# CORTEXM0: IP-XACT component
VLNV arm.com:Cortex-M0:CORTEXM0:r0p0_0

## Parameters
 = 
 = 
 = 
 = 
 = 
 = 
 = 
 = 
 = 
 = 
 = 
 = 

## Bus interfaces (logical=physical port)
AHBLite: master amba.com:AMBA3:AHBLite:r1p0_6, address space AHBLite
CortexM0_SMP: master arm.com:Cortex-M0:cm0_smp:r0p0_0
WICInterface: master arm.com:Cortex-M0:cm0_proc_wicinterface:r0p0_0
SCLK: slave arm.com:Cortex-M0:cm0_system_clk:r0p0_0
DebugTriggers: slave arm.com:CortexMCores:dbg_trigger_bus:r0p0_1
DebugSlave: slave arm.com:Cortex-M0:cm0_debug_slave:r0p0_0, memory map debug_memory
Events: master arm.com:CortexMCores:sleep_bus:r0p0_1
IRQ0: slave spiritconsortium.org:busdef.interrupt:interrupt:1.0
IRQ1: slave spiritconsortium.org:busdef.interrupt:interrupt:1.0
IRQ2: slave spiritconsortium.org:busdef.interrupt:interrupt:1.0
IRQ3: slave spiritconsortium.org:busdef.interrupt:interrupt:1.0
IRQ4: slave spiritconsortium.org:busdef.interrupt:interrupt:1.0
IRQ5: slave spiritconsortium.org:busdef.interrupt:interrupt:1.0
IRQ6: slave spiritconsortium.org:busdef.interrupt:interrupt:1.0
IRQ7: slave spiritconsortium.org:busdef.interrupt:interrupt:1.0
IRQ8: slave spiritconsortium.org:busdef.interrupt:interrupt:1.0
IRQ9: slave spiritconsortium.org:busdef.interrupt:interrupt:1.0
IRQ10: slave spiritconsortium.org:busdef.interrupt:interrupt:1.0
IRQ11: slave spiritconsortium.org:busdef.interrupt:interrupt:1.0
IRQ12: slave spiritconsortium.org:busdef.interrupt:interrupt:1.0
IRQ13: slave spiritconsortium.org:busdef.interrupt:interrupt:1.0
IRQ14: slave spiritconsortium.org:busdef.interrupt:interrupt:1.0
IRQ15: slave spiritconsortium.org:busdef.interrupt:interrupt:1.0
IRQ16: slave spiritconsortium.org:busdef.interrupt:interrupt:1.0
IRQ17: slave spiritconsortium.org:busdef.interrupt:interrupt:1.0
IRQ18: slave spiritconsortium.org:busdef.interrupt:interrupt:1.0
IRQ19: slave spiritconsortium.org:busdef.interrupt:interrupt:1.0
IRQ20: slave spiritconsortium.org:busdef.interrupt:interrupt:1.0
IRQ21: slave spiritconsortium.org:busdef.interrupt:interrupt:1.0
IRQ22: slave spiritconsortium.org:busdef.interrupt:interrupt:1.0
IRQ23: slave spiritconsortium.org:busdef.interrupt:interrupt:1.0
IRQ24: slave spiritconsortium.org:busdef.interrupt:interrupt:1.0
IRQ25: slave spiritconsortium.org:busdef.interrupt:interrupt:1.0
IRQ26: slave spiritconsortium.org:busdef.interrupt:interrupt:1.0
IRQ27: slave spiritconsortium.org:busdef.interrupt:interrupt:1.0
IRQ28: slave spiritconsortium.org:busdef.interrupt:interrupt:1.0
IRQ29: slave spiritconsortium.org:busdef.interrupt:interrupt:1.0
IRQ30: slave spiritconsortium.org:busdef.interrupt:interrupt:1.0
IRQ31: slave spiritconsortium.org:busdef.interrupt:interrupt:1.0
NMI: slave spiritconsortium.org:busdef.interrupt:interrupt:1.0

## Address spaces and blocks
AHBLite: range 3584M, width 32
Vendor_SYS: range 511M, width 32
PPB: range 1M, width 32
debug_memory.: base 0xE0001000, range 4K, width 32
debug_memory.: base 0xE0002000, range 4K, width 32
debug_memory.: base 0xE000E000, range 3K, width 32
debug_memory.: base 0xE000ED00, range 768, width 32
debug_memory.: base 0xE00FF000, range 4K, width 32
debug_memory.: base 0xE000E000, range 4K, width 32
debug_memory.: base 0xE0001000, range 4K, width 32
debug_memory.: base 0xE0002000, range 4K, width 32

## Registers
Registers are 32-bit, read-only, reset 0x0 unless marked. A register's access mark holds for its fields unless they carry their own. Offsets are from the block's base; lines under a group give offsets from that group; [hi:lo] are bit positions; {n}, {i} and the like mark numbered series; 'fields as' and 'values as' point back to an identical list; <NAME> marks a mode.

## debug_memory.block0
Base 0xE0001000
0x00 DWT_CTRL reset 0x20000000 (reset mask 0xEFFFFFFF) — Use the DW Control Register to check how many comparators are available.
  [31:28] NUMCOMP — Number of comparators. This read-only field contains 0b0010 or 0b0001 to indicate two or one comparators.
    2=Indicates two comparators; 1=Indicates one comparator
0x1C DWT_PCSR reset not defined — Use the DW Program Counter Sample Register (DWPCSR) to enable coarse-grained software profiling using a debug agent, without changing the currently executing code. If the core is not in debug state, the value returned is the instruction address of a recently executed instruction. If the core is in debug state, the value returned is 0xFFFFFFFF.
  [31:0] EIASAMPLE — Execution instruction address sample, or 0xFFFFFFFF if the core is halted
0x20 DWT_COMP0 rw reset not defined — Use the DW Comparator Registers to write the values that trigger watchpoint events
  [31:0] COMP — Value to compare against PC or the data address as given by the DWT_FUNCTION Register. A debugger must align the value to DWT_MASK, otherwise operation is UNPREDICTABLE.
0x24 DWT_MASK0 rw reset not defined — Use the DW Mask Registers to apply a mask to data addresses when matching against COMP
  [3:0] MASK — Mask applied to data address when matching against COMP. This is the size of the ignore mask.
0x28 DWT_FUNCTION0 rw reset not defined — Use the DW Function Registers to control the operation of the comparator. Each comparator can Match against either the PC or the data address and halt the core. This function is in conjunction with DWT_COMP
  [3:0] FUNCTION — Function setting
    0=Disabled; 4=Watchpoint on PC match; 5=Watchpoint on read address; 6=Watchpoint on write to address; 7=Watchpoint on read or write address
0x30 DWT_COMP1 rw reset not defined — Use the DW Comparator Registers to write the values that trigger watchpoint events
  [31:0] COMP — Value to compare against PC or the data address as given by the DWT_FUNCTION Register. A debugger must align this value to DWT_MASK, otherwise operation is UNPREDICTABLE.
0x34 DWT_MASK1 rw reset not defined — Use the DW Mask Registers to apply a mask to data addresses when matching against COMP
  fields as DWT_MASK0
0x38 DWT_FUNCTION1 rw — Use the DW Function Registers to control the operation of the comparator. Each comparator can Match against either the PC or the data address and halt the core. This function is in conjunction with DWT_COMP
  fields as DWT_FUNCTION0

## debug_memory.block1
Base 0xE0002000
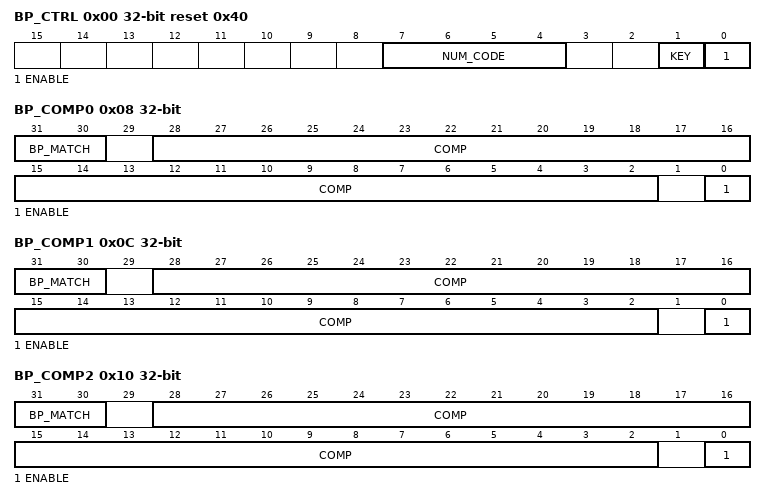
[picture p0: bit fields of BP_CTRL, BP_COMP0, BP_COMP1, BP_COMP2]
0x00 BP_CTRL rw reset 0x40 (reset mask 0x1) — Use the Breakpoint Control Register to enable the Breakpoint block
  [7:4] NUM_CODE ro — Number of comparators.
  [1] KEY wo — Key field. To write to the Breakpoint Control Register, you must write a 1 to this write-only bit. This bit reads as zero.
  [0] ENABLE — Breakpoint unit enable bit. DBGRESETn clears the ENABLE bit.
    1=Breakpoint unit enabled; 0=Breakpoint unit disabled
0x08 BP_COMP0 rw (reset mask 0x1) — Use the Breakpoint Comparator Registers to store the values to compare with the instruction address.
  [31:30] BP_MATCH — This selects what happens when the COMP address is matched
    0=no breakpoint generated; 1=set breakpoint on lower halfword, upper is unaffected; 2=set breakpoint on upper halfword, lower is unaffected; 3=set breakpoint on both lower and upper halfwords
  [28:2] COMP — Comparison address, UNKNOWN on reset.
  [0] ENABLE — Compare enable for Breakpoint Comparator Register 0. The ENABLE bit of BP_CTRL must also be set to enable comparisons. DBGRESETn clears the ENABLE bit.
    0=Breakpoint Comparator Register 0 compare disabled; 1=Breakpoint Comparator Register 0 compare enabled
0x0C BP_COMP1 rw (reset mask 0x1) — Use the Breakpoint Comparator Registers to store the values to compare with the instruction address.
  [31:30] BP_MATCH — This selects what happens when the COMP address is matched
    0=No breakpoint generated; 1=Set breakpoint on lower halfword, upper is unaffected; 2=Set breakpoint on upper halfword, lower is unaffected; 3=Set breakpoint on both lower and upper halfwords
  [28:2] COMP — Comparison address. Although it is architecturally Unpredictable whether breakpoint matches on the address of the second halfword of a 32-bit instruction to generates a debug event, in this processor it is predictable and a debug event is generated.
  [0] ENABLE — Comparison address, UNKNOWN on reset.
    0=Breakpoint Comparator Register 1 compare disabled; 1=Breakpoint Comparator Register 1 compare enabled
0x10 BP_COMP2 rw (reset mask 0x1) — Use the Breakpoint Comparator Registers to store the values to compare with the PC address.
  [31:30] BP_MATCH — This selects what happens when the COMP address is matched
    0=No breakpoint matching; 1=Set breakpoint on lower halfword, upper is unaffected; 2=Set breakpoint on upper halfword, lower is unaffected; 3=Set breakpoint on both lower and upper halfwords
  [28:2] COMP — Comparison address, UNKNOWN on reset.
  [0] ENABLE — Compare enable for Breakpoint Comparator Register 2. The ENABLE bit of BP_CTRL must also be set to enable comparisons. DBGRESETn clears the ENABLE bit.
    0=Breakpoint Comparator Register 2 compare disabled; 1=Breakpoint Comparator Register 2 compare enabled
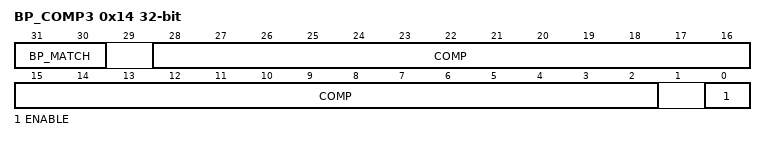
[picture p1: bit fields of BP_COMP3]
0x14 BP_COMP3 rw (reset mask 0x1) — Use the Breakpoint Comparator Registers to store the values to compare with the instruction address.
  [31:30] BP_MATCH — This selects what happens when the COMP address is matched
    values as BP_COMP1.BP_MATCH
  [28:2] COMP — Comparison address, UNKNOWN on reset.
  [0] ENABLE — Compare enable for Breakpoint Comparator Register 3. The ENABLE bit of BP_CTRL must also be set to enable comparisons. DBGRESETn clears the ENABLE bit.
    0=Breakpoint Comparator Register 3 compare disabled; 1=Breakpoint Comparator Register 3 compare enabled

## debug_memory.block2
Base 0xE000E000
0x08 ACTLR reset not defined
  [31:0] ACTLR
    0=ACTLR is RAZ
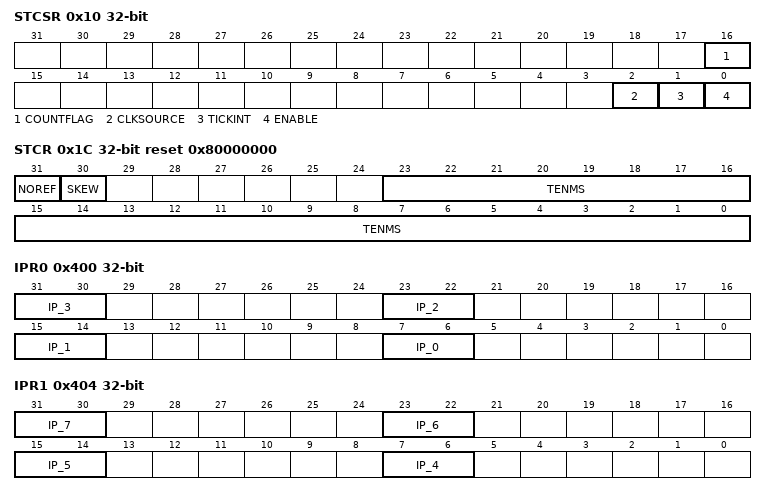
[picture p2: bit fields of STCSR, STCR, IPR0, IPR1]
0x10 STCSR rw reset not defined — Use the SysTick Control and Status Register to enable the SysTick features.
  [16] COUNTFLAG ro — Returns 1 if timer counted to 0 since last time this was read. Clears on read by application or debugger.
  [2] CLKSOURCE ro — Always reads as one if STCALIB reports NOREF. 1 = core clock. Indicates that SysTick uses the processor clock, HCLK
  [1] TICKINT
    0=counting down to zero does not pend the SysTick handler. Software can use COUNTFLAG to determine if the SysTick handler has ever counted to zero.; 1=counting down to zero pends the SysTick handler
  [0] ENABLE — Enable SysTick counter
    0=counter disabled; 1=Counter operates in a multi-shot way. That is, counter loads with the Reload value and then begins counting down. On reaching 0, it sets the COUNTFLAG to 1 and optionally pends the SysTick handler, based on TICKINT. It then loads the Reload value again, and begins counting.
0x14 STRVR rw reset not defined — Use the SysTick Reload Value Register to specify the start value to load into the current value register when the counter reaches 0. It can be any value between 0 and 0x00FFFFFF. A start value of 0 is possible, but has no effect because the SysTick interrupt and COUNTFLAG are activated when counting from 1 to 0. The reset value of this register is UNKNOWN.
  [23:0] RELOAD — Value to load into the SysTick Current Value Register when the counter reaches 0.
0x18 STCVR rw reset not defined — Use the SysTick Current Value Register to find the current value in the register. The reset value of this register is UNKNOWN.
  [23:0] CURRENT — Reads return the current value of the SysTick counter. This register is write-clear. Writing to it with any value clears the register to 0. Clearing this register also clears the COUNTFLAG bit of the SysTick Control and Status Register.
0x1C STCR reset 0x80000000 — Use the SysTick Calibration Value Register to enable software to scale to any required speed using divide and multiply.
  [31] NOREF — If reads as 1, the Reference clock is not provided - the CLKSOURCE bit of the SysTick Control and Status register will be forced to 1 and cannot be cleared to 0.
  [30] SKEW — If reads as 1, the calibration value for 10ms is inexact (due to clock frequency).
  [23:0] TENMS — An optional Reload value to be used for 10ms (100Hz) timing, subject to system clock skew errors. If the value reads as 0, the calibration value is not known.
0x100 ISER rw — Use the Interrupt Set-Enable Register to enable interrupts and determine which interrupts are currently enabled.
  [31:0] SETENA — Writing 0 to a SETENA bit has no effect, writing 1 to a bit enables the corresponding interrupt. Reading the bit returns its current enable state. Reset clears the SETENA fields.
0x180 ICER rw — Use the Interrupt Clear-Enable Registers to disable interrupts and determine which interrupts are currently enabled.
  [31:0] CLRENA — Writing 0 to a CLRENA bit has no effect, writing 1 to a bit disables the corresponding interrupt. Reading the bit returns its current enable state. Reset clears the CLRENA field.
0x200 ISPR rw — Use the Interrupt Set-Pending Register to force interrupts into the pending state and determine which interrupts are currently pending
  [31:0] SETPEND — Interrupt set-pending bits for a: Write: 1 = pend interrupt 0 = no effect; Read: 1 = interrupt is pending 0 = interrupt is not pending.
0x280 ICPR rw — Use the Interrupt Clear-Pending Register to clear pending interrupts and determine which interrupts are currently pending.
  [31:0] CLRPEND — Interrupt clear-pending bits: Write: 1 = clear interrupt pending bit, 0 = no effect; Read: 1 = interrupt is pending 0 = interrupt is not pending.
0x400 IPR0 rw — Use the Interrupt Priority Registers to assign a priority from 0 to 3 to each of the available interrupts. 0 is the highest priority, and 3 is the lowest.
  [8n+7:8n+6] IP_{n} (n=0..3) — Priority of interrupt {n}
0x404 IPR1 rw — Use the Interrupt Priority Registers to assign a priority from 0 to 3 to each of the available interrupts. 0 is the highest priority, and 3 is the lowest.
  [8n-25:8n-26] IP_{n} (n=4..7) — Priority of interrupt {n}
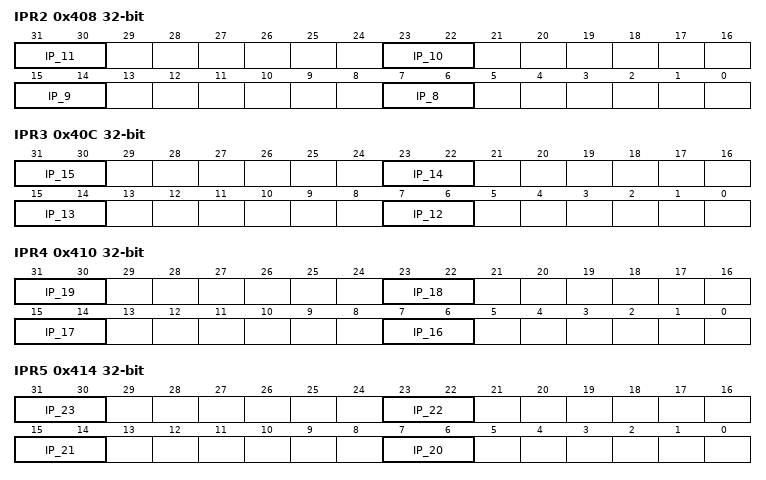
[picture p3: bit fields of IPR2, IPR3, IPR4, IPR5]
0x408 IPR2 rw — Use the Interrupt Priority Registers to assign a priority from 0 to 3 to each of the available interrupts. 0 is the highest priority, and 3 is the lowest.
  [8n-57:8n-58] IP_{n} (n=8..11) — Priority of interrupt {n}
0x40C IPR3 rw — Use the Interrupt Priority Registers to assign a priority from 0 to 3 to each of the available interrupts. 0 is the highest priority, and 3 is the lowest.
  [8n-89:8n-90] IP_{n} (n=12..15) — Priority of interrupt {n}
0x410 IPR4 rw — Use the Interrupt Priority Registers to assign a priority from 0 to 3 to each of the available interrupts. 0 is the highest priority, and 3 is the lowest.
  [8n-121:8n-122] IP_{n} (n=16..19) — Priority of interrupt {n}
0x414 IPR5 rw — Use the Interrupt Priority Registers to assign a priority from 0 to 3 to each of the available interrupts. 0 is the highest priority, and 3 is the lowest.
  [8n-153:8n-154] IP_{n} (n=20..23) — Priority of interrupt {n}
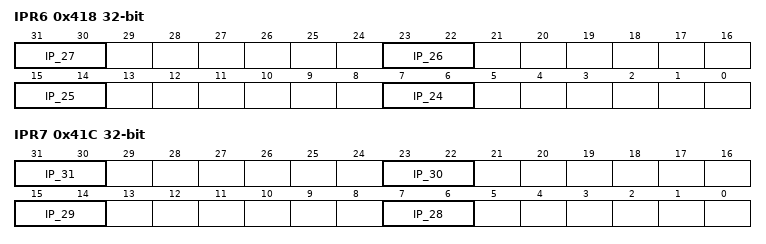
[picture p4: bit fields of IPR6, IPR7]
0x418 IPR6 rw — Use the Interrupt Priority Registers to assign a priority from 0 to 3 to each of the available interrupts. 0 is the highest priority, and 3 is the lowest.
  [8n-185:8n-186] IP_{n} (n=24..27) — Priority of interrupt {n}
0x41C IPR7 rw — Use the Interrupt Priority Registers to assign a priority from 0 to 3 to each of the available interrupts. 0 is the highest priority, and 3 is the lowest.
  [8n-217:8n-218] IP_{n} (n=28..31) — Priority of interrupt {n}

## debug_memory.block3
Base 0xE000ED00
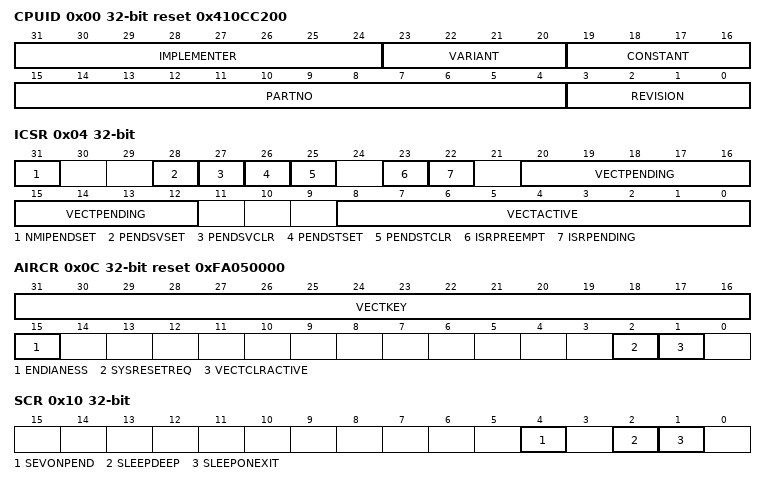
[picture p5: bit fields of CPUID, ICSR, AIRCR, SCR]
0x00 CPUID reset 0x410CC200 — Read the CPU ID Base Register to determine: the ID number of the processor core, the version number of the processor core, the implementation details of the processor core.
  [31:24] IMPLEMENTER — Implementor code: 0x41 = ARM
  [23:20] VARIANT — Implementation defined variant number: 0x0 (for r0)
  [19:16] CONSTANT — Reads as 0xC
  [15:4] PARTNO — Number of processor within family: 0xC20
  [3:0] REVISION — Implementation defined revision number: 0x0 = processor p0 revision.
0x04 ICSR rw — Use the Interrupt Control State Register to set a pending Non-Maskable Interrupt (NMI), set or clear a pending PendSV, set or clear a pending SysTick, check for pending exceptions, check the vector number of the highest priority pended exception, check the vector number of the active exception.
  [31] NMIPENDSET — Setting this bit will activate an NMI. Since NMI is the highest priority exception, it will activate as soon as it is registered. Reads back with current state (1 if Pending, 0 if not).
    0=no effect; 1=set pending NMI
  [28] PENDSVSET — Set pending PendSV bit. On reads this bit returns the pending state of PendSV
    0=no effect; 1=set pending PendSV
  [27] PENDSVCLR wo — Clear pending PendSV bit
    0=no effect; 1=clear pending PendSV
  [26] PENDSTSET — Set a pending SysTick bit. On reads this bit returns the pending state of Systick.
    0=no effect; 1=set pending SysTick
  [25] PENDSTCLR wo — Clear pending SysTick bit
    0=no effect; 1=clear pending SysTick
  [23] ISRPREEMPT ro — The system can only access this bit when the core is halted. It indicates that a pending interrupt is to be taken in the next running cycle. If C_MASKINTS is clear in the Debug Halting Control and Status Register, the interrupt is serviced.
    0=a pending exception is not serviced; 1=a pending exception is serviced on exit from the debug halt state
  [22] ISRPENDING ro — External interrupt pending flag
    0=interrupt not pending; 1=interrupt pending
  [20:12] VECTPENDING ro — Indicates the exception number for the highest priority pending exception: 0 = no pending exceptions. Non zero = The pending state includes the effect of memory-mapped enable and mask registers. It does not include the PRIMASK special-purpose register qualifier.
  [8:0] VECTACTIVE ro — Active exception number field. Reset clears the VECTACTIVE field.
0x0C AIRCR rw reset 0xFA050000 (reset mask 0xFFFF7FFF) — Use the Application Interrupt and Reset Control Register to: determine data endianness, clear all active state information from debug halt mode, request a system reset.
  [31:16] VECTKEY wo — Register key. To write to other parts of this register, you must ensure 0x5FA is written into the VECTKEY field.
  [15] ENDIANESS ro — Data endianness bit. The read value depends on the endian configuration implemented
    0=little endian; 1=BE-8 big-endian
  [2] SYSRESETREQ wo — Writing 1 to this bit causes the SYSRESETREQ signal to the outer system to be asserted to request a reset. The intention is to force a large system reset of all major components except for debug. The C_HALT bit in the DHCSR is cleared as a result of the system reset requested. The debugger does not lose contact with the device.
  [1] VECTCLRACTIVE wo — Clears all active state information for fixed and configurable exceptions. This bit: is self-clearing, can only be set by the DAP when the core is halted. When set: clears all active exception status of the processor, forces a return to Thread mode, forces an IPSR of 0. A debugger must re-initialize the stack.
0x10 SCR rw — System Control Register. Use the System Control Register for power-management functions: signal to the system when the processor can enter a low power state, control how the processor enters and exits low power states.
  [4] SEVONPEND — When enabled, this causes WFE to wake up when an interrupt moves from inactive to pended. Otherwise, WFE only wakes up from an event signal, external and SEV instruction generated. The event input, RXEV, is registered even when not waiting for an event, and so effects the next WFE.
  [2] SLEEPDEEP — Sleep deep bit.
    0=not OK to turn off system clock; 1=indicates to the system that Cortex-M0 clock can be stopped. Setting this bit causes the SLEEPDEEP port to be asserted when the processor can be stopped.
  [1] SLEEPONEXIT — Sleep on exit when returning from Handler mode to Thread mode. Enables interrupt driven applications to avoid returning to empty main application.
    0=Do not sleep when returning to thread mode; 1=Sleep on return to thread mode
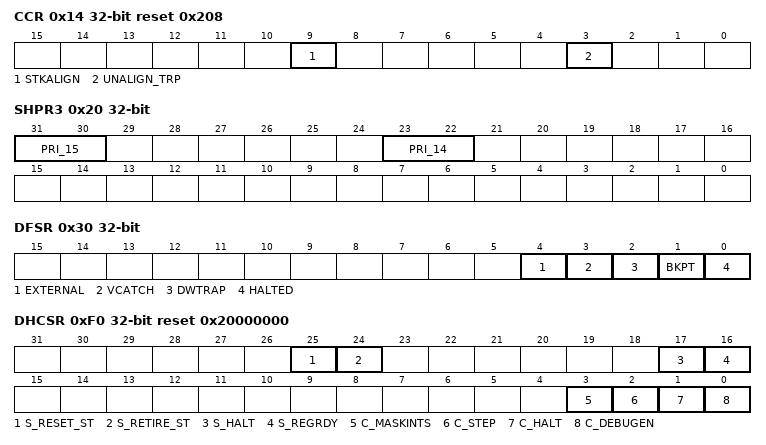
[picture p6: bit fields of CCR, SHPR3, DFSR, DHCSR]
0x14 CCR reset 0x208 — The Configuration and Control Register permanently enables stack alignment and causes unaligned accesses to result in a Hard Fault.
  [9] STKALIGN — Always set to 1. On exception entry, all exceptions are entered with 8-byte stack alignment and the context to restore it is saved. The SP is restored on the associated exception return.
  [3] UNALIGN_TRP — Indicates that all unaligned accesses results in a Hard Fault. Trap for unaligned access is fixed at 1.
0x1C SHPR2 rw — System handlers are a special class of exception handler that can have their priority set to any of the priority levels. Use the System Handler Priority Register 2 to set the priority of SVCall.
  [31:30] PRI_11 — Priority of system handler 11, SVCall
0x20 SHPR3 rw — System handlers are a special class of exception handler that can have their priority set to any of the priority levels. Use the System Handler Priority Register 3 to set the priority of PendSV and SysTick.
  [31:30] PRI_15 — Priority of system handler 15, SysTick
  [23:22] PRI_14 — Priority of system handler 14, PendSV
0x24 SHCSR rw — Use the System Handler Control and State Register to determine or clear the pending status of SVCall. This register is only accessible as part of debug and not through the processor memory map.
  [15] SVCALLPENDED — Reads as 1 if SVCall is Pending. Write 1 to set pending SVCall, write 0 to clear pending SVCall.
0x30 DFSR rw — Use the Debug Fault Status Register to monitor external debug requests, vector catches, data watchpoint match, BKPT instruction execution and BPU comparator matches, halt requests. Write one to clear. C_DEBUGEN must be set before any bits in DFSR are updated.
  [4] EXTERNAL — External debug request flag
    0=no EDBGRQ external debug request occurred; 1=EDBGRQ has halted the core
  [3] VCATCH — Vector catch flag. When the VCATCH flag is set, a flag in the Debug Exception and Monitor Control Register is also set to indicate the type of vector catch.
    0=no vector catch occurred; 1=vector catch occurred
  [2] DWTRAP — Data Watchpoint (DW) flag.
    0=no DW match; 1=DW match
  [1] BKPT — The BKPT flag is set by the execution of the BKPT instruction or on an instruction whose address triggered the breakpoint comparator match. When the processor has halted, the return PC points to the address of the breakpointed instruction.
    0=no BKPT instruction or hardware breakpoint match; 1=BKPT instruction or hardware breakpoint match
  [0] HALTED — Halt request flag
    0=no halt request; 1=halt requested by DAP access to C_HALT or halted with C_STEP asserted
0xF0 DHCSR reset 0x20000000 — The purpose of the Debug Halting Control and Status Register (DHCSR) is to provide status information about the state of the processor, enable core debug, halt and step the processor. For writes, 0xA05F must be written to bits [31:16], otherwise the write operation is ignored and no bits are written into the register.
  [25] S_RESET_ST — Indicates that the core has been reset, or is now being reset, since the last time this bit was read. This a sticky bit that clears on read. So, reading twice and getting 1 then 0 means it was reset in the past. Reading twice and getting 1 both times means that it is currently reset and held in reset.
  [24] S_RETIRE_ST — Core has retired at least part of an instruction since last read. This is a sticky bit that clears on read.
  [17] S_HALT — The core is halted in debug state only if S_HALT is set.
  [16] S_REGRDY — Register Read/Write to the Debug Core Register Selector Register is available. Set in response to a successful register access.
  [3] C_MASKINTS rw — When this bit is set and debug is enabled, external interrupts, SysTick, and PendSV are masked. Does not affect NMI, Hard Fault or SVCall. When C_DEBUGEN = 0, this bit has no effect.
  [2] C_STEP rw — Causes a debug event on any instruction or exception being executed, resulting in the core single stepping.
  [1] C_HALT rw — Halts the core. This bit is set automatically when the core triggers a debug event, for example, on a breakpoint. This bit clears on core reset. When C_DEBUGEN = 0, this bit has no effect.
  [0] C_DEBUGEN rw — Enables or disable debug
    0=Debug disabled; 1=Debug enabled
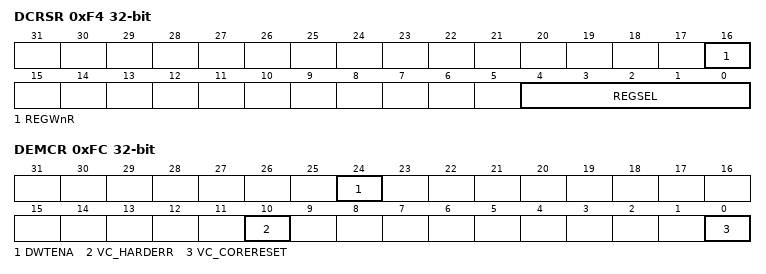
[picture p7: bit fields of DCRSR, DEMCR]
0xF4 DCRSR wo reset not defined — The purpose of the Debug Core Register Selector Register (DCRSR) is to select the processor register to transfer data to or from.
  [16] REGWnR — Write = 1, Read = 0
  [4:0] REGSEL — Select processor register
    {v}=R{v} (v=0..12); 13=Current SP; 14=LR; 15=DebugReturnAddress; 16=xPSR flags, Execution Number, and state information; 17=MSP (Main SP); 18=PSP (Process SP); 20=CONTROL (DCRDR[25:24]), PRIMASK (DCRDR[0])
0xF8 DCRDR rw reset not defined — The purpose of the Debug Core Register Data Register (DCRDR) is to hold data read from or written to core registers.
0xFC DEMCR rw — The purpose of the Debug Exception and Monitor Control Register (DEMCR) is: Global enable for the DW unit, Vector catching (that is, causes debug entry on execution of a specified vector.)
  [24] DWTENA — Global enable or disable for the DW unit
    0=DW unit disabled. Watchpoint cannot halt the core. The DW PCSR reads as OxFFFFFFFF.; 1=DW unit enabled
  [10] VC_HARDERR — Debug trap on a Hard Fault
  [0] VC_CORERESET — Reset Vector Catch. Halt running system if HRESETn is asserted

## debug_memory.block4
Base 0xE00FF000
0x00 SCS reset 0xFFF0F003 — Points to the System Control Space (SCS) at 0xE000E000. This includes core debug control registers.
0x04 DWT reset 0xFFF02003 (reset mask 0xFFFFFFFE) — Points to the DW unit at 0xE0001000.
0x08 BPU reset 0xFFF03003 (reset mask 0xFFFFFFFE) — Points to the BPU at 0xE0002000.
0x0C end — Marks of end of table. This value is fixed.
0xFCC MEMTYPE reset 0x1 — System memory map is always accessible from the DAP. Always set to 0x1.
0xFD0 PeripheralID4 reset 0x4
0xFD4 PeripheralID5 reset 0xB4
0xFD8 PeripheralID6 reset 0xB
0xFDC PeripheralID7
0xFE0 PeripheralID0 reset 0x71
0xFE4 PeripheralID1 reset 0xB4
0xFE8 PeripheralID2 reset 0xB
0xFEC PeripheralID3
0xFF0 ComponentID0 reset 0xD
0xFF4 ComponentID1 reset 0x10
0xFF8 ComponentID2 reset 0x5
0xFFC ComponentID3 reset 0xB1

## debug_memory.block5
Base 0xE000E000
0xFD0 PeripheralID4 reset 0x4
0xFE0 PeripheralID0 reset 0x8
0xFE4 PeripheralID1 reset 0xB0
0xFE8 PeripheralID2 reset 0xB
0xFEC PeripheralID3
0xFF0 ComponentID0 reset 0xD
0xFF4 ComponentID1 reset 0xE0
0xFF8 ComponentID2 reset 0x5
0xFFC ComponentID3 reset 0xB1

## debug_memory.block6
Base 0xE0001000
Registers as debug_memory.block5; these are added or differ:
0xFE0 PeripheralID0 reset 0xA

## debug_memory.block7
Base 0xE0002000
Registers as debug_memory.block5; these are added or differ:
0xFE0 PeripheralID0 reset 0xB

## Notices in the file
This confidential and proprietary software may be used only as
authorised by a licensing agreement from ARM Limited
(C) COPYRIGHT 2008-2009 ARM Limited
ALL RIGHTS RESERVED
The entire notice above must be reproduced on all authorised
copies and copies may only be made to the extent permitted
by a licensing agreement from ARM Limited.
